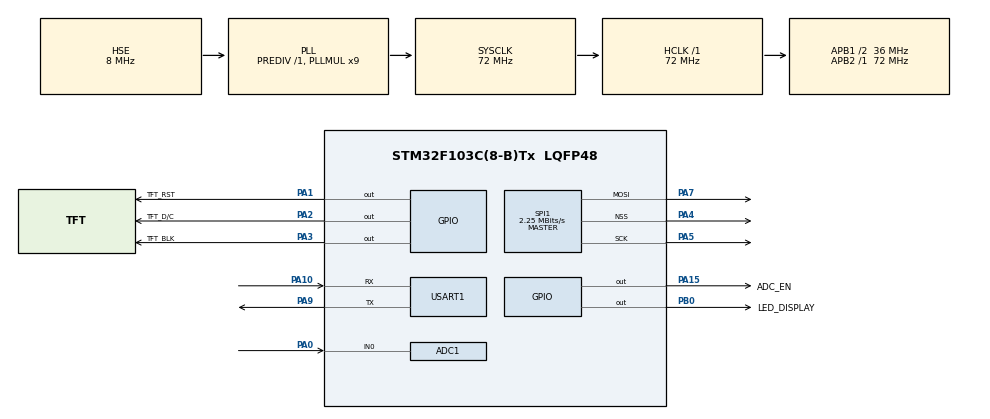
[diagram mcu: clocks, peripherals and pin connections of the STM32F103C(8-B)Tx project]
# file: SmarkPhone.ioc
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ADC1.Channel-3\#ChannelRegularConversion=ADC_CHANNEL_0
ADC1.NbrOfConversion=1
ADC1.NbrOfConversionFlag=1
ADC1.Rank-3\#ChannelRegularConversion=1
ADC1.SamplingTime-3\#ChannelRegularConversion=ADC_SAMPLETIME_1CYCLE_5
ADC1.master=1
Dma.Request0=USART1_RX
Dma.Request1=USART1_TX
Dma.USART1_RX.0.Direction=DMA_PERIPH_TO_MEMORY
Dma.USART1_RX.0.Instance=DMA1_Channel5
Dma.USART1_RX.0.MemDataAlignment=DMA_MDATAALIGN_BYTE
Dma.USART1_RX.0.MemInc=DMA_MINC_ENABLE
Dma.USART1_RX.0.Mode=DMA_NORMAL
Dma.USART1_RX.0.PeriphDataAlignment=DMA_PDATAALIGN_BYTE
Dma.USART1_RX.0.PeriphInc=DMA_PINC_DISABLE
Dma.USART1_RX.0.Priority=DMA_PRIORITY_LOW
Dma.USART1_TX.1.Direction=DMA_MEMORY_TO_PERIPH
Dma.USART1_TX.1.Instance=DMA1_Channel4
Dma.USART1_TX.1.MemDataAlignment=DMA_MDATAALIGN_BYTE
Dma.USART1_TX.1.MemInc=DMA_MINC_ENABLE
Dma.USART1_TX.1.Mode=DMA_NORMAL
Dma.USART1_TX.1.PeriphDataAlignment=DMA_PDATAALIGN_BYTE
Dma.USART1_TX.1.PeriphInc=DMA_PINC_DISABLE
Dma.USART1_TX.1.Priority=DMA_PRIORITY_LOW
FREERTOS.Tasks01=LCDTask,24,128,LcdTask,Default,NULL,Dynamic,NULL,NULL;KeyBordTask,8,128,keybordTask,Default,NULL,Dynamic,NULL,NULL;GSMTask,8,128,gsmTask,Default,NULL,Dynamic,NULL,NULL;FLASHTask,8,128,flashTask,Default,NULL,Dynamic,NULL,NULL
Mcu.Family=STM32F1
Mcu.Name=STM32F103C(8-B)Tx
Mcu.Package=LQFP48
NVIC.DMA1_Channel4_IRQn=true\:5\:0\:false\:false\:true\:true\:false\:true
NVIC.DMA1_Channel5_IRQn=true\:5\:0\:false\:false\:true\:true\:false\:true
NVIC.PriorityGroup=NVIC_PRIORITYGROUP_4
NVIC.TIM4_IRQn=true\:15\:0\:false\:false\:true\:false\:false\:true
NVIC.TimeBase=TIM4_IRQn
NVIC.TimeBaseIP=TIM4
NVIC.USART1_IRQn=true\:5\:0\:false\:false\:true\:true\:true\:true
PA0-WKUP.Signal=ADCx_IN0
PA1.GPIO_Label=TFT_RST
PA1.PinState=GPIO_PIN_SET
PA1.Signal=GPIO_Output
PA10.Mode=Asynchronous
PA10.Signal=USART1_RX
PA13.Mode=Serial_Wire
PA13.Signal=SYS_JTMS-SWDIO
PA14.Mode=Serial_Wire
PA14.Signal=SYS_JTCK-SWCLK
PA15.GPIO_Label=ADC_EN
PA15.PinState=GPIO_PIN_SET
PA15.Signal=GPIO_Output
PA2.GPIO_Label=TFT_D/C
PA2.Signal=GPIO_Output
PA3.GPIO_Label=TFT_BLK
PA3.PinState=GPIO_PIN_SET
PA3.Signal=GPIO_Output
PA4.GPIO_Speed=GPIO_SPEED_FREQ_LOW
PA4.Mode=NSS_Signal_Hard_Output
PA4.Signal=SPI1_NSS
PA5.Mode=TX_Only_Simplex_Unidirect_Master
PA5.Signal=SPI1_SCK
PA7.Mode=TX_Only_Simplex_Unidirect_Master
PA7.Signal=SPI1_MOSI
PA9.Mode=Asynchronous
PA9.Signal=USART1_TX
PB0.GPIO_Label=LED_DISPLAY
PB0.PinState=GPIO_PIN_SET
PB0.Signal=GPIO_Output
PC14-OSC32_IN.Mode=LSE-External-Oscillator
PC14-OSC32_IN.Signal=RCC_OSC32_IN
PC15-OSC32_OUT.Mode=LSE-External-Oscillator
PC15-OSC32_OUT.Signal=RCC_OSC32_OUT
PD0-OSC_IN.Mode=HSE-External-Oscillator
PD0-OSC_IN.Signal=RCC_OSC_IN
PD1-OSC_OUT.Mode=HSE-External-Oscillator
PD1-OSC_OUT.Signal=RCC_OSC_OUT
ProjectManager.HeapSize=0x200
ProjectManager.StackSize=0x400
ProjectManager.TargetToolchain=MDK-ARM V5.32
RCC.ADCPresc=RCC_ADCPCLK2_DIV6
RCC.AHBFreq_Value=72000000
RCC.APB1CLKDivider=RCC_HCLK_DIV2
RCC.APB1Freq_Value=36000000
RCC.APB1TimFreq_Value=72000000
RCC.APB2Freq_Value=72000000
RCC.APB2TimFreq_Value=72000000
RCC.HCLKFreq_Value=72000000
RCC.PLLMUL=RCC_PLL_MUL9
RCC.PLLSourceVirtual=RCC_PLLSOURCE_HSE
RCC.SYSCLKFreq_VALUE=72000000
RCC.SYSCLKSource=RCC_SYSCLKSOURCE_PLLCLK
RCC.USBFreq_Value=72000000
SH.ADCx_IN0.0=ADC1_IN0,IN0
SPI1.BaudRatePrescaler=SPI_BAUDRATEPRESCALER_32
SPI1.CalculateBaudRate=2.25 MBits/s
SPI1.Direction=SPI_DIRECTION_2LINES
SPI1.Mode=SPI_MODE_MASTER
SPI1.VirtualNSS=VM_NSSHARD
SPI1.VirtualType=VM_MASTER
USART1.VirtualMode=VM_ASYNC
VP_FREERTOS_VS_CMSIS_V2.Mode=CMSIS_V2
VP_SYS_VS_tim4.Mode=TIM4
board=custom

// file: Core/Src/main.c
/* USER CODE BEGIN Header */
/**
  ******************************************************************************
  * @file           : main.c
  * @brief          : Main program body
  ******************************************************************************
  * @attention
  *
  * <h2><center>&copy; Copyright (c) 2023 STMicroelectronics.
  * All rights reserved.</center></h2>
  *
  * This software component is licensed by ST under Ultimate Liberty license
  * SLA0044, the "License"; You may not use this file except in compliance with
  * the License. You may obtain a copy of the License at:
  *                             www.st.com/SLA0044
  *
  ******************************************************************************
  */
/* USER CODE END Header */
#include "main.h"
#include "cmsis_os.h"
#include "adc.h"
#include "dma.h"
#include "spi.h"
#include "usart.h"
#include "gpio.h"

void SystemClock_Config(void);
void MX_FREERTOS_Init(void);

int main(void)
{

  /* MCU Configuration--------------------------------------------------------*/

  /* Reset of all peripherals, Initializes the Flash interface and the Systick. */
  HAL_Init();

  /* Configure the system clock */
  SystemClock_Config();

  /* Initialize all configured peripherals */
  MX_GPIO_Init();
  MX_ADC1_Init();
  MX_DMA_Init();
  MX_SPI1_Init();
  MX_USART1_UART_Init();

  /* Init scheduler */
  osKernelInitialize();  /* Call init function for freertos objects (in freertos.c) */
  MX_FREERTOS_Init();
  /* Start scheduler */
  osKernelStart();

  /* We should never get here as control is now taken by the scheduler */
  /* Infinite loop */
  while (1)
  {

  }
}

void SystemClock_Config(void)
{
  RCC_OscInitTypeDef RCC_OscInitStruct = {0};
  RCC_ClkInitTypeDef RCC_ClkInitStruct = {0};
  RCC_PeriphCLKInitTypeDef PeriphClkInit = {0};

  /** Initializes the RCC Oscillators according to the specified parameters
  * in the RCC_OscInitTypeDef structure.
  */
  RCC_OscInitStruct.OscillatorType = RCC_OSCILLATORTYPE_HSE;
  RCC_OscInitStruct.HSEState = RCC_HSE_ON;
  RCC_OscInitStruct.HSEPredivValue = RCC_HSE_PREDIV_DIV1;
  RCC_OscInitStruct.HSIState = RCC_HSI_ON;
  RCC_OscInitStruct.PLL.PLLState = RCC_PLL_ON;
  RCC_OscInitStruct.PLL.PLLSource = RCC_PLLSOURCE_HSE;
  RCC_OscInitStruct.PLL.PLLMUL = RCC_PLL_MUL9;
  if (HAL_RCC_OscConfig(&RCC_OscInitStruct) != HAL_OK)
  {
    Error_Handler();
  }
  /** Initializes the CPU, AHB and APB buses clocks
  */
  RCC_ClkInitStruct.ClockType = RCC_CLOCKTYPE_HCLK|RCC_CLOCKTYPE_SYSCLK
                              |RCC_CLOCKTYPE_PCLK1|RCC_CLOCKTYPE_PCLK2;
  RCC_ClkInitStruct.SYSCLKSource = RCC_SYSCLKSOURCE_PLLCLK;
  RCC_ClkInitStruct.AHBCLKDivider = RCC_SYSCLK_DIV1;
  RCC_ClkInitStruct.APB1CLKDivider = RCC_HCLK_DIV2;
  RCC_ClkInitStruct.APB2CLKDivider = RCC_HCLK_DIV1;

  if (HAL_RCC_ClockConfig(&RCC_ClkInitStruct, FLASH_LATENCY_2) != HAL_OK)
  {
    Error_Handler();
  }
  PeriphClkInit.PeriphClockSelection = RCC_PERIPHCLK_ADC;
  PeriphClkInit.AdcClockSelection = RCC_ADCPCLK2_DIV6;
  if (HAL_RCCEx_PeriphCLKConfig(&PeriphClkInit) != HAL_OK)
  {
    Error_Handler();
  }
}

void HAL_TIM_PeriodElapsedCallback(TIM_HandleTypeDef *htim)
{
  if (htim->Instance == TIM4) {
    HAL_IncTick();
  }
}

void Error_Handler(void)
{
  __disable_irq();
  while (1)
  {
  }
}

/************************ (C) COPYRIGHT STMicroelectronics *****END OF FILE****/

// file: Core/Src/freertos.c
/* USER CODE BEGIN Header */
/**
  ******************************************************************************
  * File Name          : freertos.c
  * Description        : Code for freertos applications
  ******************************************************************************
  * @attention
  *
  * <h2><center>&copy; Copyright (c) 2023 STMicroelectronics.
  * All rights reserved.</center></h2>
  *
  * This software component is licensed by ST under Ultimate Liberty license
  * SLA0044, the "License"; You may not use this file except in compliance with
  * the License. You may obtain a copy of the License at:
  *                             www.st.com/SLA0044
  *
  ******************************************************************************
  */
/* USER CODE END Header */

#include "FreeRTOS.h"
#include "task.h"
#include "main.h"
#include "cmsis_os.h"

/* USER CODE BEGIN Includes */
#include "Lcd_Driver.h"
#include "QDTFT_demo.h"
/* USER CODE END Includes */

/* Definitions for LCDTask */
osThreadId_t LCDTaskHandle;
const osThreadAttr_t LCDTask_attributes = {
  .name = "LCDTask",
  .stack_size = 128 * 4,
  .priority = (osPriority_t) osPriorityNormal,
};
/* Definitions for KeyBordTask */
osThreadId_t KeyBordTaskHandle;
const osThreadAttr_t KeyBordTask_attributes = {
  .name = "KeyBordTask",
  .stack_size = 128 * 4,
  .priority = (osPriority_t) osPriorityLow,
};
/* Definitions for GSMTask */
osThreadId_t GSMTaskHandle;
const osThreadAttr_t GSMTask_attributes = {
  .name = "GSMTask",
  .stack_size = 128 * 4,
  .priority = (osPriority_t) osPriorityLow,
};
/* Definitions for FLASHTask */
osThreadId_t FLASHTaskHandle;
const osThreadAttr_t FLASHTask_attributes = {
  .name = "FLASHTask",
  .stack_size = 128 * 4,
  .priority = (osPriority_t) osPriorityLow,
};

void LcdTask(void *argument);
void keybordTask(void *argument);
void gsmTask(void *argument);
void flashTask(void *argument);

void MX_FREERTOS_Init(void); /* (MISRA C 2004 rule 8.1) */

void MX_FREERTOS_Init(void) {

  /* Create the thread(s) */
  /* creation of LCDTask */
  LCDTaskHandle = osThreadNew(LcdTask, NULL, &LCDTask_attributes);

  /* creation of KeyBordTask */
  KeyBordTaskHandle = osThreadNew(keybordTask, NULL, &KeyBordTask_attributes);

  /* creation of GSMTask */
  GSMTaskHandle = osThreadNew(gsmTask, NULL, &GSMTask_attributes);

  /* creation of FLASHTask */
  FLASHTaskHandle = osThreadNew(flashTask, NULL, &FLASHTask_attributes);

}

void LcdTask(void *argument)
{
  /* USER CODE BEGIN LcdTask */
  /* Infinite loop */
	Lcd_Init();
	Redraw_Mainmenu();
  for(;;)
  {
    osDelay(1);
  }
  /* USER CODE END LcdTask */
}

void keybordTask(void *argument)
{
  /* USER CODE BEGIN keybordTask */
  /* Infinite loop */
  for(;;)
  {
		HAL_GPIO_TogglePin(GPIOB,GPIO_PIN_0);
    osDelay(100);
  }
  /* USER CODE END keybordTask */
}

void gsmTask(void *argument)
{
  for(;;)
  {
    osDelay(1);
  }
}

void flashTask(void *argument)
{
  for(;;)
  {
    osDelay(1);
  }
}

/************************ (C) COPYRIGHT STMicroelectronics *****END OF FILE****/
